# ioam3358 register map
Registers are 32-bit, access not given, no defined reset value unless marked. A register's access mark holds for its fields unless they carry their own. Addresses are absolute; registers are grouped by the start of their names; [hi:lo] are bit positions; {n}, {i} and the like mark numbered series.

## EMIF
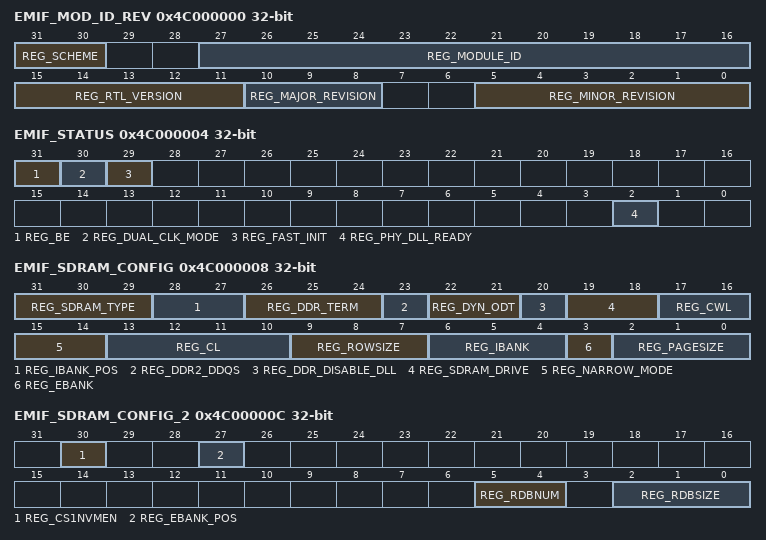
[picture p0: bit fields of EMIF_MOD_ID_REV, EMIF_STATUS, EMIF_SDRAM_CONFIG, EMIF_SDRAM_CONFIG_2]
0x4C000000 EMIF_MOD_ID_REV
  [31:30] REG_SCHEME, [27:16] REG_MODULE_ID, [15:11] REG_RTL_VERSION, [10:8] REG_MAJOR_REVISION, [5:0] REG_MINOR_REVISION
0x4C000004 EMIF_STATUS
  [31] REG_BE, [30] REG_DUAL_CLK_MODE, [29] REG_FAST_INIT, [2] REG_PHY_DLL_READY
0x4C000008 EMIF_SDRAM_CONFIG
  [31:29] REG_SDRAM_TYPE, [28:27] REG_IBANK_POS, [26:24] REG_DDR_TERM, [23] REG_DDR2_DDQS, [22:21] REG_DYN_ODT, [20] REG_DDR_DISABLE_DLL, [19:18] REG_SDRAM_DRIVE, [17:16] REG_CWL, [15:14] REG_NARROW_MODE, [13:10] REG_CL, [9:7] REG_ROWSIZE, [6:4] REG_IBANK, [3] REG_EBANK, [2:0] REG_PAGESIZE
0x4C00000C EMIF_SDRAM_CONFIG_2
  [30] REG_CS1NVMEN, [27] REG_EBANK_POS, [5:4] REG_RDBNUM, [2:0] REG_RDBSIZE
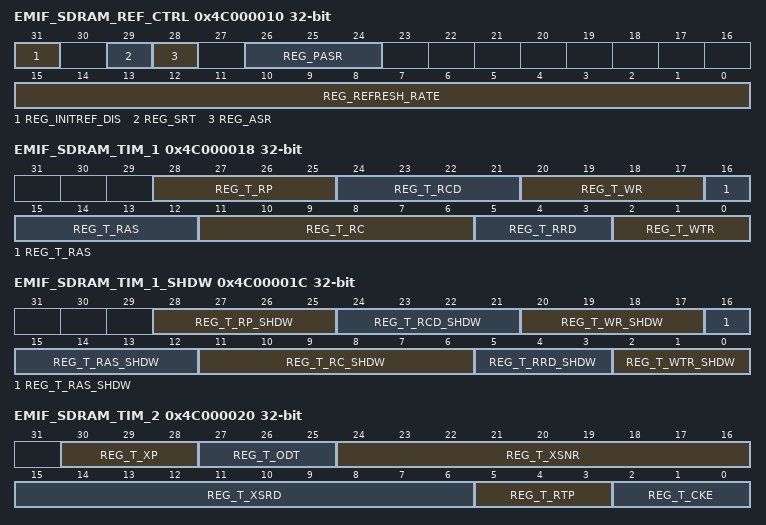
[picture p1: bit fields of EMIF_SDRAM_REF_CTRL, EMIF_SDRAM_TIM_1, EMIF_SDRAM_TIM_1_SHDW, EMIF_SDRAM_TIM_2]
0x4C000010 EMIF_SDRAM_REF_CTRL
  [31] REG_INITREF_DIS, [29] REG_SRT, [28] REG_ASR, [26:24] REG_PASR, [15:0] REG_REFRESH_RATE
0x4C000014 EMIF_SDRAM_REF_CTRL_SHDW
  [15:0] REG_REFRESH_RATE_SHDW
0x4C000018 EMIF_SDRAM_TIM_1
  [28:25] REG_T_RP, [24:21] REG_T_RCD, [20:17] REG_T_WR, [16:12] REG_T_RAS, [11:6] REG_T_RC, [5:3] REG_T_RRD, [2:0] REG_T_WTR
0x4C00001C EMIF_SDRAM_TIM_1_SHDW
  [28:25] REG_T_RP_SHDW, [24:21] REG_T_RCD_SHDW, [20:17] REG_T_WR_SHDW, [16:12] REG_T_RAS_SHDW, [11:6] REG_T_RC_SHDW, [5:3] REG_T_RRD_SHDW, [2:0] REG_T_WTR_SHDW
0x4C000020 EMIF_SDRAM_TIM_2
  [30:28] REG_T_XP, [27:25] REG_T_ODT, [24:16] REG_T_XSNR, [15:6] REG_T_XSRD, [5:3] REG_T_RTP, [2:0] REG_T_CKE
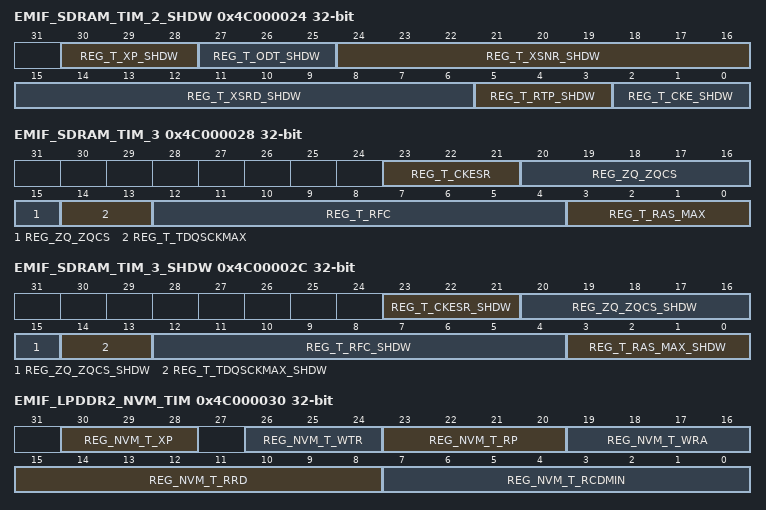
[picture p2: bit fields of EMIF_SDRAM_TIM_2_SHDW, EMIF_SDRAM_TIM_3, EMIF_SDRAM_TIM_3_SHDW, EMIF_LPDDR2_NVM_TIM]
0x4C000024 EMIF_SDRAM_TIM_2_SHDW
  [30:28] REG_T_XP_SHDW, [27:25] REG_T_ODT_SHDW, [24:16] REG_T_XSNR_SHDW, [15:6] REG_T_XSRD_SHDW, [5:3] REG_T_RTP_SHDW, [2:0] REG_T_CKE_SHDW
0x4C000028 EMIF_SDRAM_TIM_3
  [23:21] REG_T_CKESR, [20:15] REG_ZQ_ZQCS, [14:13] REG_T_TDQSCKMAX, [12:4] REG_T_RFC, [3:0] REG_T_RAS_MAX
0x4C00002C EMIF_SDRAM_TIM_3_SHDW
  [23:21] REG_T_CKESR_SHDW, [20:15] REG_ZQ_ZQCS_SHDW, [14:13] REG_T_TDQSCKMAX_SHDW, [12:4] REG_T_RFC_SHDW, [3:0] REG_T_RAS_MAX_SHDW
0x4C000030 EMIF_LPDDR2_NVM_TIM
  [30:28] REG_NVM_T_XP, [26:24] REG_NVM_T_WTR, [23:20] REG_NVM_T_RP, [19:16] REG_NVM_T_WRA, [15:8] REG_NVM_T_RRD, [7:0] REG_NVM_T_RCDMIN
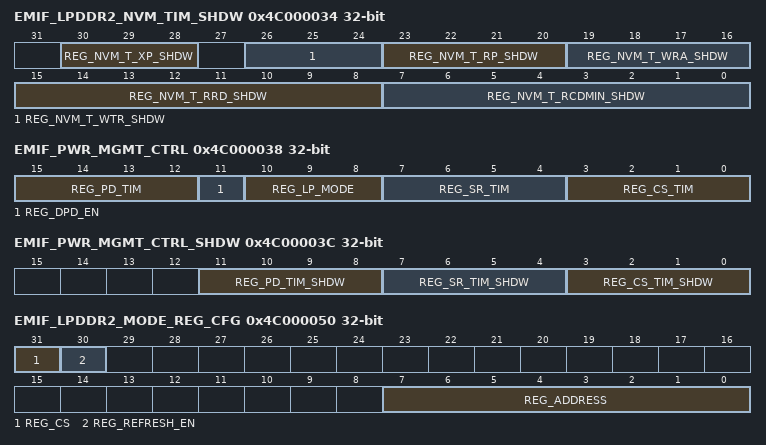
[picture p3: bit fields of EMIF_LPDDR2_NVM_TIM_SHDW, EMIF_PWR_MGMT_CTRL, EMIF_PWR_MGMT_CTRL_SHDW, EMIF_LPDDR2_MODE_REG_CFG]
0x4C000034 EMIF_LPDDR2_NVM_TIM_SHDW
  [30:28] REG_NVM_T_XP_SHDW, [26:24] REG_NVM_T_WTR_SHDW, [23:20] REG_NVM_T_RP_SHDW, [19:16] REG_NVM_T_WRA_SHDW, [15:8] REG_NVM_T_RRD_SHDW, [7:0] REG_NVM_T_RCDMIN_SHDW
0x4C000038 EMIF_PWR_MGMT_CTRL
  [15:12] REG_PD_TIM, [11] REG_DPD_EN, [10:8] REG_LP_MODE, [7:4] REG_SR_TIM, [3:0] REG_CS_TIM
0x4C00003C EMIF_PWR_MGMT_CTRL_SHDW
  [11:8] REG_PD_TIM_SHDW, [7:4] REG_SR_TIM_SHDW, [3:0] REG_CS_TIM_SHDW
0x4C000040 EMIF_LPDDR2_MODE_REG_DATA
  [6:0] REG_VALUE_0
0x4C000050 EMIF_LPDDR2_MODE_REG_CFG
  [31] REG_CS, [30] REG_REFRESH_EN, [7:0] REG_ADDRESS
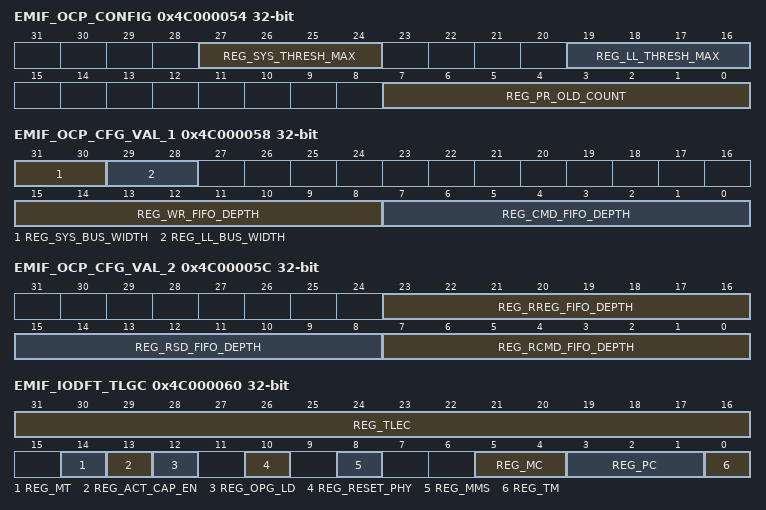
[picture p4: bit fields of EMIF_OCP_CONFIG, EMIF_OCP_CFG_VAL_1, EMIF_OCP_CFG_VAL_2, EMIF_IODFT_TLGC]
0x4C000054 EMIF_OCP_CONFIG
  [27:24] REG_SYS_THRESH_MAX, [19:16] REG_LL_THRESH_MAX, [7:0] REG_PR_OLD_COUNT
0x4C000058 EMIF_OCP_CFG_VAL_1
  [31:30] REG_SYS_BUS_WIDTH, [29:28] REG_LL_BUS_WIDTH, [15:8] REG_WR_FIFO_DEPTH, [7:0] REG_CMD_FIFO_DEPTH
0x4C00005C EMIF_OCP_CFG_VAL_2
  [23:16] REG_RREG_FIFO_DEPTH, [15:8] REG_RSD_FIFO_DEPTH, [7:0] REG_RCMD_FIFO_DEPTH
0x4C000060 EMIF_IODFT_TLGC
  [31:16] REG_TLEC, [14] REG_MT, [13] REG_ACT_CAP_EN, [12] REG_OPG_LD, [10] REG_RESET_PHY, [8] REG_MMS, [5:4] REG_MC, [3:1] REG_PC, [0] REG_TM
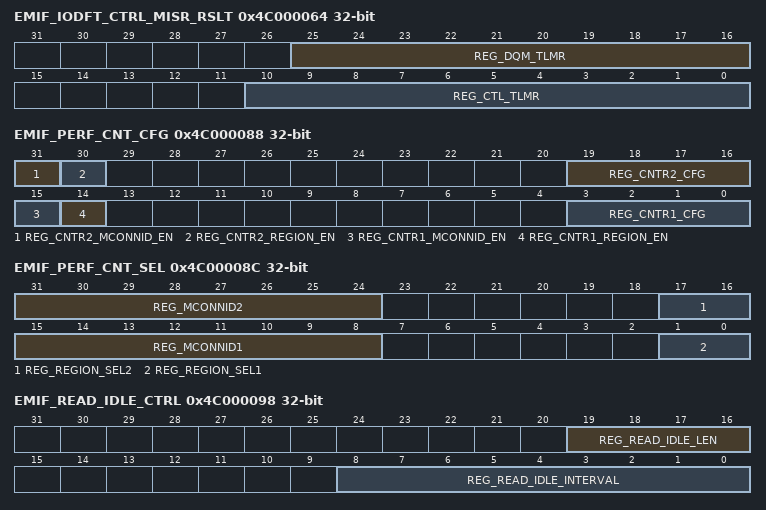
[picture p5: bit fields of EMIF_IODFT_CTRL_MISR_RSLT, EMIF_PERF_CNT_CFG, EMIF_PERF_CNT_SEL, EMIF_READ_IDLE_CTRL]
0x4C000064 EMIF_IODFT_CTRL_MISR_RSLT
  [25:16] REG_DQM_TLMR, [10:0] REG_CTL_TLMR
0x4C000068 EMIF_IODFT_ADDR_MISR_RSLT
  [20:0] REG_ADDR_TLMR
{0x4C000068+4i} EMIF_IODFT_DATA_MISR_RSLT_{i} (i=1..3)
0x4C000080 EMIF_PERF_CNT_1
0x4C000084 EMIF_PERF_CNT_2
0x4C000088 EMIF_PERF_CNT_CFG
  [31] REG_CNTR2_MCONNID_EN, [30] REG_CNTR2_REGION_EN, [19:16] REG_CNTR2_CFG, [15] REG_CNTR1_MCONNID_EN, [14] REG_CNTR1_REGION_EN, [3:0] REG_CNTR1_CFG
0x4C00008C EMIF_PERF_CNT_SEL
  [31:24] REG_MCONNID2, [17:16] REG_REGION_SEL2, [15:8] REG_MCONNID1, [1:0] REG_REGION_SEL1
0x4C000090 EMIF_PERF_CNT_TIM
0x4C000098 EMIF_READ_IDLE_CTRL
  [19:16] REG_READ_IDLE_LEN, [8:0] REG_READ_IDLE_INTERVAL
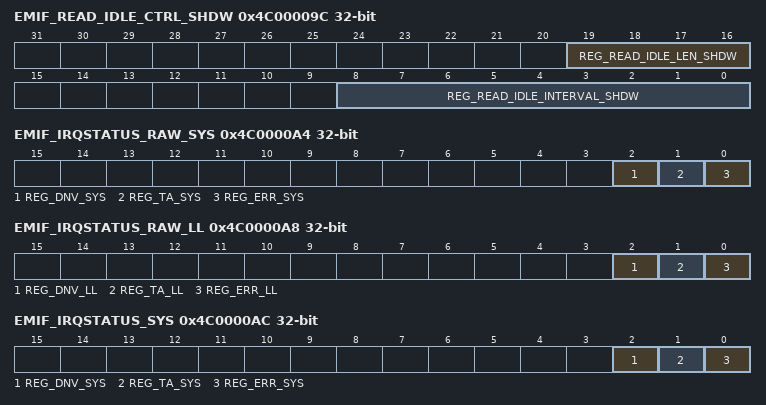
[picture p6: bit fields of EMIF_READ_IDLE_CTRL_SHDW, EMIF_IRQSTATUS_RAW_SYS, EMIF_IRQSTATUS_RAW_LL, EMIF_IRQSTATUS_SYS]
0x4C00009C EMIF_READ_IDLE_CTRL_SHDW
  [19:16] REG_READ_IDLE_LEN_SHDW, [8:0] REG_READ_IDLE_INTERVAL_SHDW
0x4C0000A0 EMIF_IRQ_EOI
  [0] REG_EOI
0x4C0000A4 EMIF_IRQSTATUS_RAW_SYS
  [2] REG_DNV_SYS, [1] REG_TA_SYS, [0] REG_ERR_SYS
0x4C0000A8 EMIF_IRQSTATUS_RAW_LL
  [2] REG_DNV_LL, [1] REG_TA_LL, [0] REG_ERR_LL
0x4C0000AC EMIF_IRQSTATUS_SYS
  [2] REG_DNV_SYS, [1] REG_TA_SYS, [0] REG_ERR_SYS
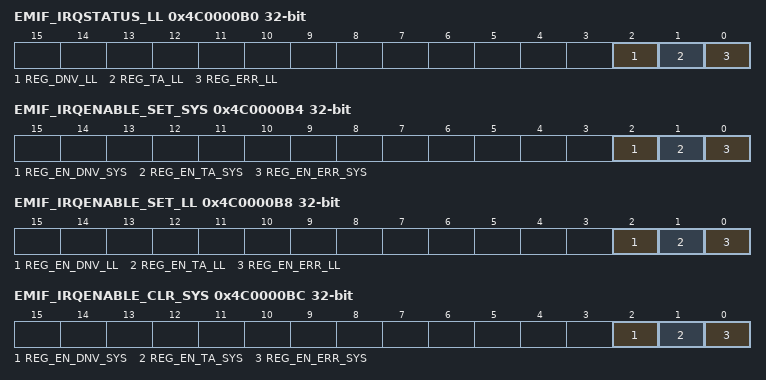
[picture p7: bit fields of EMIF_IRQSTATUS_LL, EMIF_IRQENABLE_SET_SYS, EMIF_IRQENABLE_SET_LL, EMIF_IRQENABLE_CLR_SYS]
0x4C0000B0 EMIF_IRQSTATUS_LL
  [2] REG_DNV_LL, [1] REG_TA_LL, [0] REG_ERR_LL
0x4C0000B4 EMIF_IRQENABLE_SET_SYS
  [2] REG_EN_DNV_SYS, [1] REG_EN_TA_SYS, [0] REG_EN_ERR_SYS
0x4C0000B8 EMIF_IRQENABLE_SET_LL
  [2] REG_EN_DNV_LL, [1] REG_EN_TA_LL, [0] REG_EN_ERR_LL
0x4C0000BC EMIF_IRQENABLE_CLR_SYS
  [2] REG_EN_DNV_SYS, [1] REG_EN_TA_SYS, [0] REG_EN_ERR_SYS
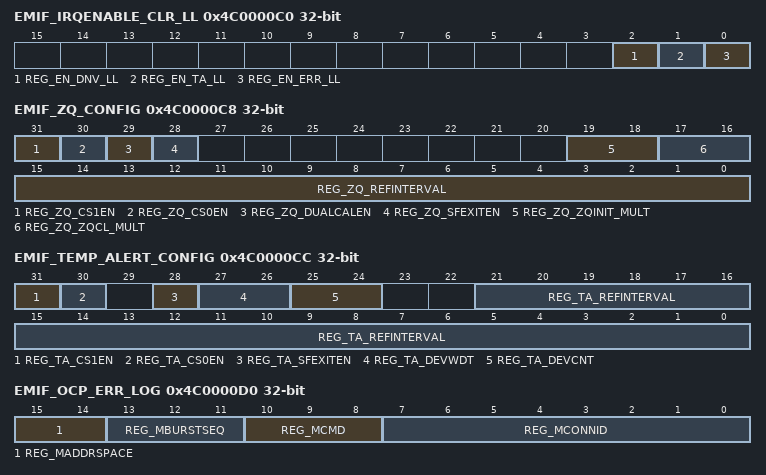
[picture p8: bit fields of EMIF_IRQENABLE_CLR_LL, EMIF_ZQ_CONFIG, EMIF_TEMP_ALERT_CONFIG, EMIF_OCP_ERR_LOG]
0x4C0000C0 EMIF_IRQENABLE_CLR_LL
  [2] REG_EN_DNV_LL, [1] REG_EN_TA_LL, [0] REG_EN_ERR_LL
0x4C0000C8 EMIF_ZQ_CONFIG
  [31] REG_ZQ_CS1EN, [30] REG_ZQ_CS0EN, [29] REG_ZQ_DUALCALEN, [28] REG_ZQ_SFEXITEN, [19:18] REG_ZQ_ZQINIT_MULT, [17:16] REG_ZQ_ZQCL_MULT, [15:0] REG_ZQ_REFINTERVAL
0x4C0000CC EMIF_TEMP_ALERT_CONFIG
  [31] REG_TA_CS1EN, [30] REG_TA_CS0EN, [28] REG_TA_SFEXITEN, [27:26] REG_TA_DEVWDT, [25:24] REG_TA_DEVCNT, [21:0] REG_TA_REFINTERVAL
0x4C0000D0 EMIF_OCP_ERR_LOG
  [15:14] REG_MADDRSPACE, [13:11] REG_MBURSTSEQ, [10:8] REG_MCMD, [7:0] REG_MCONNID
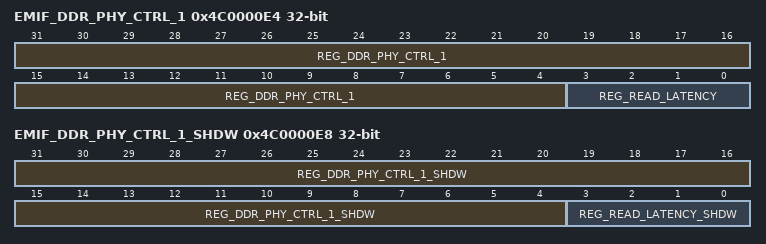
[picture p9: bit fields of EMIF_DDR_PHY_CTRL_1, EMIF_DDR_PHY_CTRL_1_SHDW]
0x4C0000E4 EMIF_DDR_PHY_CTRL_1
  [31:4] REG_DDR_PHY_CTRL_1, [3:0] REG_READ_LATENCY
0x4C0000E8 EMIF_DDR_PHY_CTRL_1_SHDW
  [31:4] REG_DDR_PHY_CTRL_1_SHDW, [3:0] REG_READ_LATENCY_SHDW
0x4C0000EC EMIF_DDR_PHY_CTRL_2
  [31:0] REG_DDR_PHY_CTRL_2
